AUTOSAR XML (schema 00051)
package /Components
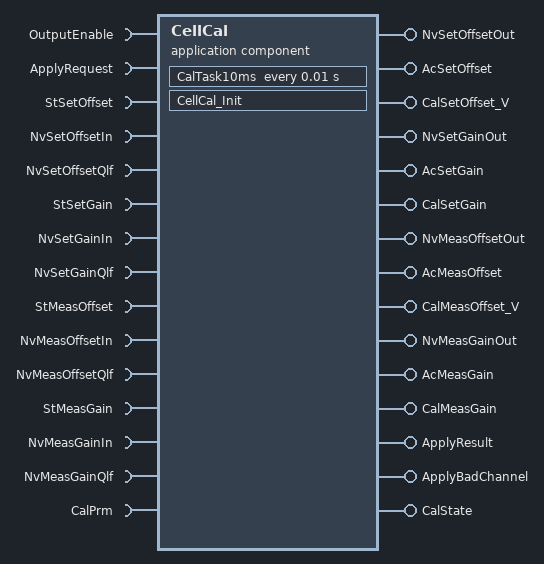
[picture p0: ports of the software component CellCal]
  application sw component type CellCal
    14 x require port:
      OutputEnable: nonqueued-receiver-com-spec{data-element=OutputEnable, init-value=0}, required-interface=OutputEnable
      ApplyRequest: nonqueued-receiver-com-spec{data-element=ApplyRequest, init-value=0}, required-interface=ApplyRequest
      StSetOffset: nonqueued-receiver-com-spec{data-element=StSetOffset, init-value=14 x 0}, required-interface=StSetOffset
      NvSetOffsetIn: nonqueued-receiver-com-spec{data-element=NvSetOffsetIn, init-value=14 x 0}, required-interface=NvSetOffsetIn
      NvSetOffsetQlf: nonqueued-receiver-com-spec{data-element=NvSetOffsetQlf, init-value=0}, required-interface=NvSetOffsetQlf
      StSetGain: nonqueued-receiver-com-spec{data-element=StSetGain, init-value=14 x 0}, required-interface=StSetGain
      NvSetGainIn: nonqueued-receiver-com-spec{data-element=NvSetGainIn, init-value=14 x 0}, required-interface=NvSetGainIn
      NvSetGainQlf: nonqueued-receiver-com-spec{data-element=NvSetGainQlf, init-value=0}, required-interface=NvSetGainQlf
      StMeasOffset: nonqueued-receiver-com-spec{data-element=StMeasOffset, init-value=14 x 0}, required-interface=StMeasOffset
      NvMeasOffsetIn: nonqueued-receiver-com-spec{data-element=NvMeasOffsetIn, init-value=14 x 0}, required-interface=NvMeasOffsetIn
      NvMeasOffsetQlf: nonqueued-receiver-com-spec{data-element=NvMeasOffsetQlf, init-value=0}, required-interface=NvMeasOffsetQlf
      StMeasGain: nonqueued-receiver-com-spec{data-element=StMeasGain, init-value=14 x 0}, required-interface=StMeasGain
      NvMeasGainIn: nonqueued-receiver-com-spec{data-element=NvMeasGainIn, init-value=14 x 0}, required-interface=NvMeasGainIn
      NvMeasGainQlf: nonqueued-receiver-com-spec{data-element=NvMeasGainQlf, init-value=0}, required-interface=NvMeasGainQlf
    15 x provide port:
      NvSetOffsetOut: nonqueued-sender-com-spec{data-element=NvSetOffsetOut, init-value=14 x 0}, provided-interface=NvSetOffsetOut
      AcSetOffset: nonqueued-sender-com-spec{data-element=AcSetOffset, init-value=14 x 0}, provided-interface=AcSetOffset
      CalSetOffset_V: nonqueued-sender-com-spec{data-element=CalSetOffset_V, init-value=14 x 0}, provided-interface=CalSetOffset_V
      NvSetGainOut: nonqueued-sender-com-spec{data-element=NvSetGainOut, init-value=14 x 0}, provided-interface=NvSetGainOut
      AcSetGain: nonqueued-sender-com-spec{data-element=AcSetGain, init-value=14 x 0}, provided-interface=AcSetGain
      CalSetGain: nonqueued-sender-com-spec{data-element=CalSetGain, init-value=14 x 0}, provided-interface=CalSetGain
      NvMeasOffsetOut: nonqueued-sender-com-spec{data-element=NvMeasOffsetOut, init-value=14 x 0}, provided-interface=NvMeasOffsetOut
      AcMeasOffset: nonqueued-sender-com-spec{data-element=AcMeasOffset, init-value=14 x 0}, provided-interface=AcMeasOffset
      CalMeasOffset_V: nonqueued-sender-com-spec{data-element=CalMeasOffset_V, init-value=14 x 0}, provided-interface=CalMeasOffset_V
      NvMeasGainOut: nonqueued-sender-com-spec{data-element=NvMeasGainOut, init-value=14 x 0}, provided-interface=NvMeasGainOut
      AcMeasGain: nonqueued-sender-com-spec{data-element=AcMeasGain, init-value=14 x 0}, provided-interface=AcMeasGain
      CalMeasGain: nonqueued-sender-com-spec{data-element=CalMeasGain, init-value=14 x 0}, provided-interface=CalMeasGain
      ApplyResult: nonqueued-sender-com-spec{data-element=ApplyResult, init-value=0}, provided-interface=ApplyResult
      ApplyBadChannel: nonqueued-sender-com-spec{data-element=ApplyBadChannel, init-value=0}, provided-interface=ApplyBadChannel
      CalState: nonqueued-sender-com-spec{data-element=CalState, init-value=0}, provided-interface=CalState
    require port CalPrm: required-interface=CalPrm
      required-com-specs:
        init-value=CalPrm_GainMax_code:11000, parameter=GainMax_code
        init-value=CalPrm_GainMin_code:9000, parameter=GainMin_code
        init-value=CalPrm_OffsetLimit_code:2000, parameter=OffsetLimit_code
    behavior CellCal_IB: handle-termination-and-restart=NO-SUPPORT
      timing event Event_CalTask10ms: start-on-event=CalTask10ms, period=0.01
      runnable CellCal_Init
      runnable CalTask10ms
        data-receive-point-by-arguments:
          14 x access:
            IN_ApplyRequest_ApplyRequest: accessed-variable=ApplyRequest.ApplyRequest
            IN_NvMeasGainIn_NvMeasGainIn: accessed-variable=NvMeasGainIn.NvMeasGainIn
            IN_NvMeasGainQlf_NvMeasGainQlf: accessed-variable=NvMeasGainQlf.NvMeasGainQlf
            IN_NvMeasOffsetIn_NvMeasOffsetIn: accessed-variable=NvMeasOffsetIn.NvMeasOffsetIn
            IN_NvMeasOffsetQlf_NvMeasOffsetQlf: accessed-variable=NvMeasOffsetQlf.NvMeasOffsetQlf
            IN_NvSetGainIn_NvSetGainIn: accessed-variable=NvSetGainIn.NvSetGainIn
            IN_NvSetGainQlf_NvSetGainQlf: accessed-variable=NvSetGainQlf.NvSetGainQlf
            IN_NvSetOffsetIn_NvSetOffsetIn: accessed-variable=NvSetOffsetIn.NvSetOffsetIn
            IN_NvSetOffsetQlf_NvSetOffsetQlf: accessed-variable=NvSetOffsetQlf.NvSetOffsetQlf
            IN_OutputEnable_OutputEnable: accessed-variable=OutputEnable.OutputEnable
            IN_StMeasGain_StMeasGain: accessed-variable=StMeasGain.StMeasGain
            IN_StMeasOffset_StMeasOffset: accessed-variable=StMeasOffset.StMeasOffset
            IN_StSetGain_StSetGain: accessed-variable=StSetGain.StSetGain
            IN_StSetOffset_StSetOffset: accessed-variable=StSetOffset.StSetOffset
        data-send-points:
          15 x access:
            OUT_NvSetOffsetOut_NvSetOffsetOut: accessed-variable=NvSetOffsetOut.NvSetOffsetOut
            OUT_AcSetOffset_AcSetOffset: accessed-variable=AcSetOffset.AcSetOffset
            OUT_CalSetOffset_V_CalSetOffset_V: accessed-variable=CalSetOffset_V.CalSetOffset_V
            OUT_NvSetGainOut_NvSetGainOut: accessed-variable=NvSetGainOut.NvSetGainOut
            OUT_AcSetGain_AcSetGain: accessed-variable=AcSetGain.AcSetGain
            OUT_CalSetGain_CalSetGain: accessed-variable=CalSetGain.CalSetGain
            OUT_NvMeasOffsetOut_NvMeasOffsetOut: accessed-variable=NvMeasOffsetOut.NvMeasOffsetOut
            OUT_AcMeasOffset_AcMeasOffset: accessed-variable=AcMeasOffset.AcMeasOffset
            OUT_CalMeasOffset_V_CalMeasOffset_V: accessed-variable=CalMeasOffset_V.CalMeasOffset_V
            OUT_NvMeasGainOut_NvMeasGainOut: accessed-variable=NvMeasGainOut.NvMeasGainOut
            OUT_AcMeasGain_AcMeasGain: accessed-variable=AcMeasGain.AcMeasGain
            OUT_CalMeasGain_CalMeasGain: accessed-variable=CalMeasGain.CalMeasGain
            OUT_ApplyResult_ApplyResult: accessed-variable=ApplyResult.ApplyResult
            OUT_ApplyBadChannel_ApplyBadChannel: accessed-variable=ApplyBadChannel.ApplyBadChannel
            OUT_CalState_CalState: accessed-variable=CalState.CalState
        parameter access CALPRM_CalPrm_GainMax_code: accessed-parameter=CalPrm.GainMax_code
        parameter access CALPRM_CalPrm_GainMin_code: accessed-parameter=CalPrm.GainMin_code
        parameter access CALPRM_CalPrm_OffsetLimit_code: accessed-parameter=CalPrm.OffsetLimit_code
      variation point proxy CellCount: category=VALUE, value-access=integer-value-variation-point=CellCount
